# TC37XPD register map
Vendor: Infineon; Series: ATVMC; File version: 100
CPU: other r0p0, little endian, MPU, FPU, vendor SysTick, 4 interrupt priority bits
Registers are 32-bit, read-write, reset 0x0 unless marked. A register's access mark holds for its fields unless they carry their own. Offsets are from the block's base; [hi:lo] are bit positions; lines under a group give offsets from that group; {n}, {i} and the like mark numbered series.

## ASCLIN0
Base 0xF0000600
Same registers: ASCLIN{n} {0xF0000600+0x100*n} (n=1..9), ASCLIN10 0xF02C0A00, ASCLIN11 0xF02C0B00
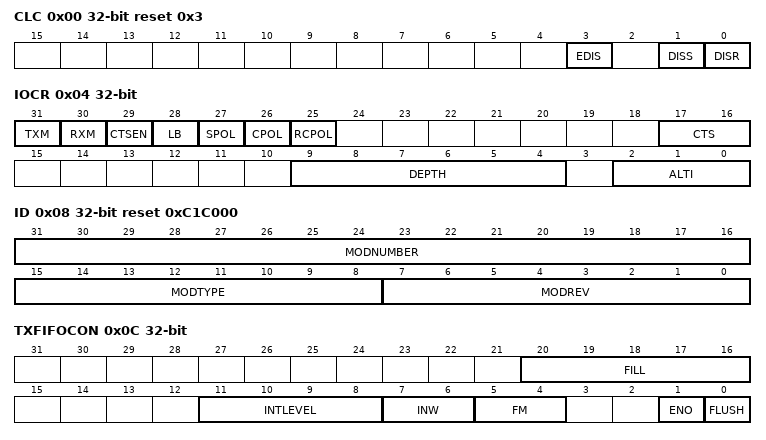
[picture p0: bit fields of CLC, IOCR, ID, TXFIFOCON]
0x00 CLC access per field reset 0x3 — Clock Control Register resetvalue={Application Reset:0x3}
  [3] EDIS rw — Sleep Mode Enable Control EDIS. Used to control module s sleep mode that is if the sensitivity of the module to the sleep signal is enabled to react to it or disabled to ignore it.
  [1] DISS ro — Module Disable Status Bit DISS. Bit indicates the current status of the module.
  [0] DISR rw — Module Disable Request Bit DISR. Used for enable disable control of the module.
0x04 IOCR access per field (reset mask 0xFFFFFFF) — Input and Output Control Register resetvalue={Application Reset:0x0}
  [31] TXM ro — Transmit Monitor TXM. Shows the status of the transmit signal.
  [30] RXM ro — Receive Monitor RXM. Shows the status of the receive signal.
  [29] CTSEN rw — Input Signal CTS Enable CTSEN. Enables the sensitivity of the module to the external CTS signal. If disabled the CTS signal is considered being permanently active.
  [28] LB rw — Loop Back Mode LB. Enables the in module connection of the transmit signal to receive signal. If Loop back is enabled the module can be run and tested without an external connection in ASC and SPI modes. In LIN mode loopback should not be used because the module can be either master or slave.
  [27] SPOL rw — Slave Polarity in Synchronous Mode SPOL. Defines the idle level of the SLSO signal which is the level outside the data transmission leading and trailing time intervals.
  [26] CPOL rw — Clock Polarity in Synchronous Mode CPOL. CPOL defines the idle level of the clock signal if the module is set in the SPI mode. The idle level is the level outside the data transmission time intervals. Default is low level.
  [25] RCPOL rw — RTS CTS Polarity RCPOL. RCPOL defines the active level or the RTS and CTS signals. Active means ready clear to send.
  [17:16] CTS rw — CTS Select CTS. Selects the CTS input pin out of maximum four possible.
  [9:4] DEPTH rw — Digital Glitch Filter Depth DEPTH. DEPTH determines the number of port input samples clocked with microticks that are taken into account for the calculation of the floating average. The higher the DEPTH is chosen to be the longer the glitches that are suppressed and the longer the delay of the input signal introduced by this filter.
  [2:0] ALTI rw — Alternate Input Select ALTI. Selects the alternate input for the RX signal
0x08 ID ro reset 0xC1C000 (reset mask 0xFFFFFF00) — Module Identification Register resetvalue={Application Reset:0x0C1C000}
  [31:16] MODNUMBER — Module Number Value MODNUMBER. This bit field together with MODTYPE uniquely identifies a module.
  [15:8] MODTYPE — Module Type MODTYPE. This bit field is C0 H . It defines a 32 bit module.
  [7:0] MODREV — Module Revision Number MODREV. MODREV defines the module revision number. The value of a module revision starts with 01 H first revision .
0x0C TXFIFOCON access per field — TX FIFO Configuration Register resetvalue={Application Reset:0x0}
  [20:16] FILL ro — FIFO Filling Level FILL. Read only bit field containing the current filling level of the FIFO.
  [11:8] INTLEVEL rw — FIFO Interrupt Level INTLEVEL. Defines the filling level that triggers a re fill interrupt or DMA access. An interrupt is generated when the filling level falls to INTLEVEL or below each time when a data byte is taken out of the FIFO. This behavior corresponds to the Combined Compatibility Mode of interrupt generation. See also Single Move Mode and Batch Move Mode for two additional modes.
  [7:6] INW rw — Transmit FIFO Inlet Width INW. Defines the number of bytes written to the Tx FIFO with one FPI bus write.
  [5:4] FM rw — TXFIFO Mode FM. Selects between the TXFIFO Modes.
  [1] ENO rw — Transmit FIFO Outlet Enable ENO. Enables the TxFIFO outlet. In SPI and ASC modes data transmission starts immediately when the data is available whereas in LIN case the transmission start is controlled by the protocol engine.
  [0] FLUSH wo — Flush the transmit FIFO FLUSH. Write of 1 brings the Tx FIFO in empty state. Write of 0 has no effect.
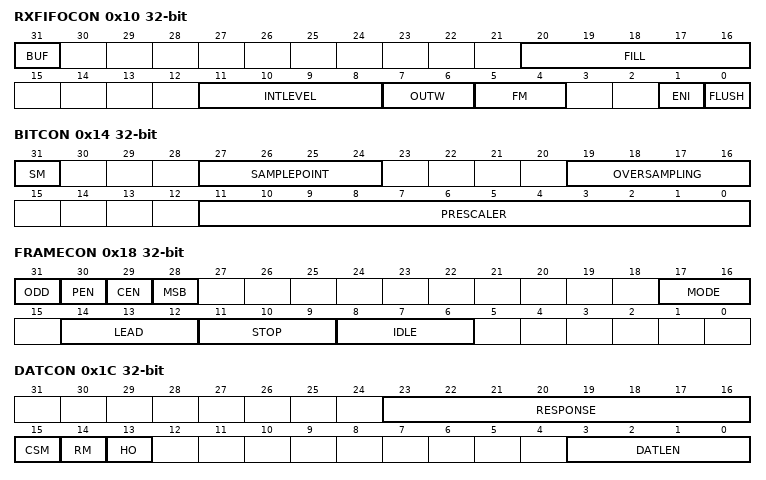
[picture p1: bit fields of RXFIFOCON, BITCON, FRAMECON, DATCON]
0x10 RXFIFOCON access per field — RX FIFO Configuration Register resetvalue={Application Reset:0x0}
  [31] BUF rw — Receive Buffer Mode BUF. If this bit is zero then the RXFIFO behaves normally as described in this document. If this bit is set the RXFIFO behaves as simple 32 bit one stage RX buffer which is overwritten with each new received data. The received bits appear in the RXDATA register on the lowest bit locations. The upper locations are padded with zeros.
  [20:16] FILL ro — FIFO Filling Level FILL. Read only bit field containing the current filling level of the FIFO.
  [11:8] INTLEVEL rw — FIFO Interrupt Level INTLEVEL. Defines the filling level that triggers a drain interrupt or DMA access. An interrupt is generated when the filling level rises to INTLEVEL or beyond each time when a data byte is delivered to the FIFO. This behavior corresponds to the Combined Compatibility Mode of interrupt generation. See also Single Move Mode and Batch Move Mode for two additional modes.
  [7:6] OUTW rw — Receive FIFO Outlet Width OUTW. Defines the number of bytes read to the Rx FIFO with one FPI bus read.
  [5:4] FM rw — RXFIFO Mode FM. Selects between the RXFIFO Modes.
  [1] ENI rw — Receive FIFO Inlet Enable ENI. Enables the receiver and the filling of the Rx FIFO through the shift register. In LIN slave mode this bit is set by hardware after the correct reception of the sync byte. The software can clear this bit after reception of an foreign ID in order to suppress the reception of the following response.
  [0] FLUSH wo — Flush the receive FIFO FLUSH. Write of 1 brings the Rx FIFO in empty state. Write of 0 has no effect.
0x14 BITCON — Bit Configuration Register resetvalue={Application Reset:0x0}
  [31] SM — Sample Mode SM. Number of samples per bit.
  [27:24] SAMPLEPOINT — Sample Point Position SAMPLEPOINT. Programmable in the range of 0 to 15 according to the CROSSREFERENCE . For example if three sample points at position 7 8 9 are required this bit field would contain 9. In SPI mode this bit field 1 defines the length of the first SCLK half period in ticks. Values equal or higher then the OVERSAMPLING value are forbidden.
  [19:16] OVERSAMPLING — Oversampling Factor OVERSAMPLING. Defines the bit length in ticks in the range of 1 to 16. The lengths of 1 to 3 are not allowed. The position of the sampling points is shown in CROSSREFERENCE .
  [11:0] PRESCALER — Prescaling of the Fractional Divider PRESCALER. Prescaler bit field with values in the range of 0 to 4095 defining division ratios from 1 to 4096. Used also as a microtick generator for the input digital filter.
0x18 FRAMECON — Frame Control Register resetvalue={Application Reset:0x0}
  [31] ODD — Parity Type ODD. Defines the type of parity bit attached to the data bits. This setting is valid for all modes of operation ASC LIN SPI .
  [30] PEN — Parity Enable PEN. Enables the parity bit attached to the data bits. Parity bit can be used for ASC and SPI protocols. The standard LIN bytes do not use this parity bit.
  [29] CEN — Collision Detection Enable CEN. Enables the collision detection mechanism.
  [28] MSB — Shift Direction MSB. Defines the shift direction of the shift register. Relevant for the SPI mode. In ASC and LIN modes should be set to zero. Parity bit is shifted out last independently of the shift direction.
  [17:16] MODE — Mode Selection MODE. This bit field defines the basic operating mode of the module. In INIT mode all outputs are at inactive level and the module does not respond to the input signals. Changing the mode of the module must be done by switching first to INIT mode and then to the other mode. The SCLK signal generated by the module is active only in the SPI mode. The CTS output generated by the module is active only in the ASC mode.
  [14:12] LEAD — Duration of the Leading Delay LEAD. Defines the leading delay in bit times in SPI mode. Has no meaning in the ASC mode. In LIN mode this is a delay inserted between the end of the break and the start of the sync character.
  [11:9] STOP — Number of Stop Bits STOP. Defines the number of stop bits in ASC and LIN mode or the trailing delay in SPI mode. In ASC mode standard values are 1 and 2. In LIN mode standard value is 1. In SPI mode there is no standard value. Nevertheless all settings are possible in all modes.
  [8:6] IDLE — Duration of the IDLE delay IDLE. Defines the duration of the IDLE delay in bit times. If more characters are available in the TXFIFO this is the pause inserted between the characters. In the SPI mode this is the idle time between the frames. In the ASC and LIN mode this is the pause inserted between transmission of bytes. Idle also applies to the pause between the header and the response response space . The collision detection runs in parallel to the idle delay and in LIN master mode it may extend the time between two bytes for one bit length. This effect may occur if the round trip delay including the digital filter delay is longer than the idle delay. For LIN slave mode use IDLE 0.
0x1C DATCON — Data Configuration Register resetvalue={Application Reset:0x0}
  [23:16] RESPONSE — Response Timeout Threshold Value RESPONSE. Defines the timer limit in the range of 1 to 256 bit times.
  [15] CSM — Checksum Mode CSM. Defines if the classic or the enhanced checksum will be calculated by the checksum block.
  [14] RM — Response Mode RM. Defines if the RESPONSE bit field defines a LIN Response or LIN Frame timeout threshold. See CROSSREFERENCE .
  [13] HO — Header Only HO. Defines if the LIN frame shall consist of a header and response or of a header only.
  [3:0] DATLEN — Data Length DATLEN. Defines the number of bits in a character. In the ASC mode standard length is 7 8 or 9 bits. In the SPI mode there is no standard length. In ASC and SPI modes any length from 2 to 16 bits is possible although not standard for some protocols. In LIN mode standard length is 8 bits per character. Therefore this field defines the number of data bytes of the response.
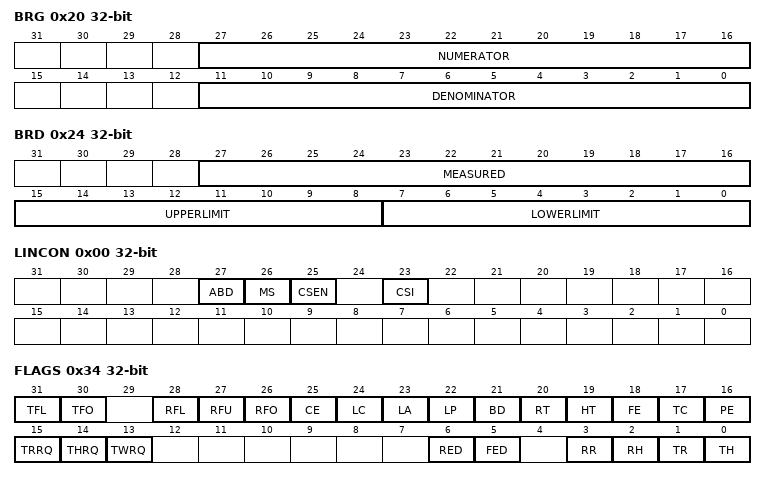
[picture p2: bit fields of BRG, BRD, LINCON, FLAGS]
0x20 BRG — Baud Rate Generation Register resetvalue={Application Reset:0x0}
  [27:16] NUMERATOR — Numerator NUMERATOR. Defines the numerator of the fractional divider in a range of 0 to 4095. Programmed by software. The setting of 0 is not allowed.
  [11:0] DENOMINATOR — Denominator DENOMINATOR. Programmed by software in a range of 0 to 4095. The setting of 0 is not allowed If the module is used as ASC SPI LIN master and LIN slave without autobaud detection this value determines the baud rate. In slave mode with autobaud detection it contains the nominal value. For the value measured by the autobaud detection hardware see the BRD register.
0x24 BRD access per field — Baud Rate Detection Register resetvalue={Application Reset:0x0}
  [27:16] MEASURED ro — Measured Value of 8 bits from Sync Field MEASURED. This bit field contains the measured value of the duration of 8 bits form the sync field of the LIN header in microticks. It is automatically loaded in the denominator of the fractional divider in case of LIN slave operation with autobaud detection.
  [15:8] UPPERLIMIT rw — Upper Limit UPPERLIMIT. This field defines the 8 most significant bits of the 12 bit compare value. The lower four bits are 1000 . See CROSSREFERENCE .
  [7:0] LOWERLIMIT rw — Lower Limit LOWERLIMIT. This field defines the 8 most significant bits of the 12 bit compare value. The lower four bits are 1000 . See CROSSREFERENCE .
0x28 LIN group
  0x00 LINCON — LIN Control Register resetvalue={Application Reset:0x0}
    [27] ABD — Autobaud Detection ABD. Enables the autobaud detection feature in LIN slave mode. In all other operating modes of the module LIN master ASC SPI not effective. If the autobaud detection is disabled the oscillator precision of the slave is sufficient the sync field byte field and stop bit is checked if correct. If not correct a framing error is triggered.
    [26] MS — Master Slave Mode MS. Configures if the module in LIN mode operates as master or as slave.
    [25] CSEN — Hardware Checksum Enable CSEN. Enables the hardware checksum generation and checking.
    [23] CSI — Checksum Injection CSI. Defines if the received checksum byte is written into the RXFIFO or not. See CROSSREFERENCE .
  0x04 LINBTIMER — LIN Break Timer Register resetvalue={Application Reset:0x0}
    [5:0] BREAK — Break Pulse Generation and Detection BREAK. In LIN slave mode this bit field defines the duration of the detection threshold for the break pulse. In LIN master mode this bit field defines the duration of the transmitted break pulse. The time unit is bit time.
  0x08 LINHTIMER — LIN Header Timer Register resetvalue={Application Reset:0x0}
    [7:0] HEADER — Header Timeout Threshold Value HEADER. Defines the timer limit in the range of 0 to 255 bit times.
0x34 FLAGS ro — Flags Register resetvalue={Application Reset:0x0}
  [31] TFL — Transmit FIFO Level Flag TFL. This flag signals whenever a TXFIFO refill interrupt if enabled is generated based on TXFIFOCON.FM mode.
  [30] TFO — Transmit FIFO Overflow Flag TFO. Signals an overflow error. If enabled an error interrupt is triggered.
  [28] RFL — Receive FIFO Level Flag RFL. This flag signals whenever a RXFIFO fill interrupt is generated based on RXFIFOCON.FM mode.
  [27] RFU — Receive FIFO Underflow Flag RFU. Signals an underflow error. If enabled an error interrupt is triggered. See also CROSSREFERENCE .
  [26] RFO — Receive FIFO Overflow Flag RFO. Signals an overflow error. If enabled an error interrupt is triggered.
  [25] CE — Collision Detection Error Flag CE. When transmitting signals if the transmitted data differs from the received data. If enabled an error interrupt is triggered in case of a mismatch. Collision detection is mandatory only when supporting LIN version 2.1.
  [24] LC — LIN Checksum Error Flag LC. Signals checksum error when receiving response if the internally calculated checksum is different than the received checksum. If enabled an error interrupt is triggered.
  [23] LA — LIN Autobaud Detection Error Flag LA. Signals baudrate outside the range defined by BRD .LOWERLIMIT and BRD .UPPERLIMIT.
  [22] LP — LIN Parity Error Flag LP. Signals parity error in the LIN identifier. If enabled an error interrupt is triggered. Applies to LIN mode only. LIN parity error occurs if the internally calculated parity bits are not equal to the received parity bits.
  [21] BD — Break Detected Flag BD. Signals a detection of a break pulse. If enabled an error interrupt is triggered. Slave mode only.
  [20] RT — Response Timeout Flag RT. Signals violation of the response or frame duration limit as defined in DATCON .RM bit. If enabled an error interrupt is triggered.
  [19] HT — Header Timeout Flag HT. Signals violation of the header duration limit. If enabled an error interrupt is triggered.
  [18] FE — Framing Error Flag FE. Signals framing error. If enabled an error interrupt is triggered. Framing error occurs if 0 is received at a stop bit position. If autobaud detection is deactivated then the sync field is checked for framing error.
  [17] TC — Transmission Completed Flag TC. Signals an end of an ASC or SPI frame. This bit is set after the last stop bit transmission in ASC mode or after the trailing delay in case of SPI mode. In LIN mode if the node is transmitting a header this flag is set after each transmission break incl lead field Sync field or PID field. If the node is transmitting a response this flag is set after each byte is transmitted. If enabled an EX interrupt is triggered. Should be cleared by software.
  [16] PE — Parity Error Flag PE. Signals parity error. If enabled an error interrupt is triggered. Parity error occurs if the internally calculated parity bit is not equal to the received parity bit.
  [15] TRRQ — Transmit Response Request Flag TRRQ. Signals that transmission of response has been requested. No interrupt triggered. As soon as the response transmission starts the bit is cleared by the hardware.
  [14] THRQ — Transmit Header Request Flag THRQ. Signals that transmission of header has been requested. No interrupt triggered. As soon as the header transmission starts the bit is cleared by the hardware.
  [13] TWRQ — Transmit Wake Request Flag TWRQ. Signals that transmission of wake has been requested. No interrupt triggered. As soon as the wake pulse transmission starts the bit is cleared by the hardware.
  [6] RED — Rising Edge from Level 0 to Level 1 Detected RED. This bit is set by hardware when a rising edge is detected on the RX line.
  [5] FED — Falling Edge from Level 1 to Level 0 Detected FED. This bit is set by hardware when a falling edge is detected on the RX line.
  [3] RR — Receive Response End Flag RR. Signals that RESPONSE RX END event. Set by hardware clear by software. If enabled a receive interrupt is triggered.
  [2] RH — Receive Header End Flag RH. Signals that HEADER RX END event. Set by hardware clear by software. If enabled a receive interrupt is triggered.
  [1] TR — Transmit Response End Flag TR. Signals that RESPONSE TX END event. Set by hardware clear by software. If enabled a transmit interrupt is triggered.
  [0] TH — Transmit Header End Flag TH. Signals the HEADER TX END event. Set by hardware clear by software. If enabled a transmit interrupt is triggered.
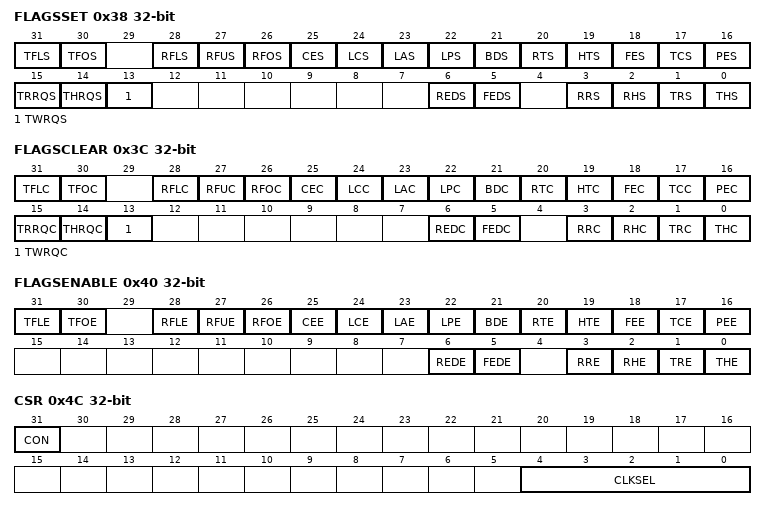
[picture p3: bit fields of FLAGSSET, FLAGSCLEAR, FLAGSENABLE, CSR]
0x38 FLAGSSET wo — Flags Set Register resetvalue={Application Reset:0x0}
  [31] TFLS — Flag Set Bit TFLS. Write of 8220 1 8221 in this bit sets the bit at the corresponding position in the FLAGS register.
  [30] TFOS — Flag Set Bit TFOS. Write of 8220 1 8221 in this bit sets the bit at the corresponding position in the FLAGS register.
  [28] RFLS — Flag Set Bit RFLS. Write of 8220 1 8221 in this bit sets the bit at the corresponding position in the FLAGS register.
  [27] RFUS — Flag Set Bit RFUS. Write of 8220 1 8221 in this bit sets the bit at the corresponding position in the FLAGS register.
  [26] RFOS — Flag Set Bit RFOS. Write of 8220 1 8221 in this bit sets the bit at the corresponding position in the FLAGS register.
  [25] CES — Flag Set Bit CES. Write of 8220 1 8221 in this bit sets the bit at the corresponding position in the FLAGS register.
  [24] LCS — Flag Set Bit LCS. Write of 8220 1 8221 in this bit sets the bit at the corresponding position in the FLAGS register.
  [23] LAS — Flag Set Bit LAS. Write of 8220 1 8221 in this bit sets the bit at the corresponding position in the FLAGS register.
  [22] LPS — Flag Set Bit LPS. Write of 8220 1 8221 in this bit sets the bit at the corresponding position in the FLAGS register.
  [21] BDS — Flag Set Bit BDS. Write of 8220 1 8221 in this bit sets the bit at the corresponding position in the FLAGS register.
  [20] RTS — Flag Set Bit RTS. Write of 8220 1 8221 in this bit sets the bit at the corresponding position in the FLAGS register.
  [19] HTS — Flag Set Bit HTS. Write of 8220 1 8221 in this bit sets the bit at the corresponding position in the FLAGS register.
  [18] FES — Flag Set Bit FES. Write of 8220 1 8221 in this bit sets the bit at the corresponding position in the FLAGS register.
  [17] TCS — Flag Set Bit TCS. Write of 8220 1 8221 in this bit sets the bit at the corresponding position in the FLAGS register.
  [16] PES — Flag Set Bit PES. Write of 8220 1 8221 in this bit sets the bit at the corresponding position in the FLAGS register.
  [15] TRRQS — Flag Set Bit TRRQS. Write of 8220 1 8221 in this bit sets the bit at the corresponding position in the FLAGS register.
  [14] THRQS — Flag Set Bit THRQS. Write of 8220 1 8221 in this bit sets the bit at the corresponding position in the FLAGS register.
  [13] TWRQS — Flag Set Bit TWRQS. Write of 8220 1 8221 in this bit sets the bit at the corresponding position in the FLAGS register.
  [6] REDS — Flag Set Bit REDS. Write of 8220 1 8221 in this bit sets the bit at the corresponding position in the FLAGS register.
  [5] FEDS — Flag Set Bit FEDS. Write of 8220 1 8221 in this bit sets the bit at the corresponding position in the FLAGS register.
  [3] RRS — Flag Set Bit RRS. Write of 8220 1 8221 in this bit sets the bit at the corresponding position in the FLAGS register.
  [2] RHS — Flag Set Bit RHS. Write of 8220 1 8221 in this bit sets the bit at the corresponding position in the FLAGS register.
  [1] TRS — Flag Set Bit TRS. Write of 8220 1 8221 in this bit sets the bit at the corresponding position in the FLAGS register.
  [0] THS — Flag Set Bit THS. Write of 8220 1 8221 in this bit sets the bit at the corresponding position in the FLAGS register.
0x3C FLAGSCLEAR wo — Flags Clear Register resetvalue={Application Reset:0x0}
  [31] TFLC — Flag Clear Bit TFLC. Write of 8220 1 8221 in this bit clears the bit at the corresponding position in the FLAGS register.
  [30] TFOC — Flag Clear Bit TFOC. Write of 8220 1 8221 in this bit clears the bit at the corresponding position in the FLAGS register.
  [28] RFLC — Flag Clear Bit RFLC. Write of 8220 1 8221 in this bit clears the bit at the corresponding position in the FLAGS register.
  [27] RFUC — Flag Clear Bit RFUC. Write of 8220 1 8221 in this bit clears the bit at the corresponding position in the FLAGS register.
  [26] RFOC — Flag Clear Bit RFOC. Write of 8220 1 8221 in this bit clears the bit at the corresponding position in the FLAGS register.
  [25] CEC — Flag Clear Bit CEC. Write of 8220 1 8221 in this bit clears the bit at the corresponding position in the FLAGS register.
  [24] LCC — Flag Clear Bit LCC. Write of 8220 1 8221 in this bit clears the bit at the corresponding position in the FLAGS register.
  [23] LAC — Flag Clear Bit LAC. Write of 8220 1 8221 in this bit clears the bit at the corresponding position in the FLAGS register.
  [22] LPC — Flag Clear Bit LPC. Write of 8220 1 8221 in this bit clears the bit at the corresponding position in the FLAGS register.
  [21] BDC — Flag Clear Bit BDC. Write of 8220 1 8221 in this bit clears the bit at the corresponding position in the FLAGS register.
  [20] RTC — Flag Clear Bit RTC. Write of 8220 1 8221 in this bit clears the bit at the corresponding position in the FLAGS register.
  [19] HTC — Flag Clear Bit HTC. Write of 8220 1 8221 in this bit clears the bit at the corresponding position in the FLAGS register.
  [18] FEC — Flag Clear Bit FEC. Write of 8220 1 8221 in this bit clears the bit at the corresponding position in the FLAGS register.
  [17] TCC — Flag Clear Bit TCC. Write of 8220 1 8221 in this bit clears the bit at the corresponding position in the FLAGS register.
  [16] PEC — Flag Clear Bit PEC. Write of 8220 1 8221 in this bit clears the bit at the corresponding position in the FLAGS register.
  [15] TRRQC — Flag Clear Bit TRRQC. Write of 8220 1 8221 in this bit clears the bit at the corresponding position in the FLAGS register.
  [14] THRQC — Flag Clear Bit THRQC. Write of 8220 1 8221 in this bit clears the bit at the corresponding position in the FLAGS register.
  [13] TWRQC — Flag Clear Bit TWRQC. Write of 8220 1 8221 in this bit clears the bit at the corresponding position in the FLAGS register.
  [6] REDC — Flag Clear Bit REDC. Write of 8220 1 8221 in this bit clears the bit at the corresponding position in the FLAGS register.
  [5] FEDC — Flag Clear Bit FEDC. Write of 8220 1 8221 in this bit clears the bit at the corresponding position in the FLAGS register.
  [3] RRC — Flag Clear Bit RRC. Write of 8220 1 8221 in this bit clears the bit at the corresponding position in the FLAGS register.
  [2] RHC — Flag Clear Bit RHC. Write of 8220 1 8221 in this bit clears the bit at the corresponding position in the FLAGS register.
  [1] TRC — Flag Clear Bit TRC. Write of 8220 1 8221 in this bit clears the bit at the corresponding position in the FLAGS register.
  [0] THC — Flag Clear Bit THC. Write of 8220 1 8221 in this bit clears the bit at the corresponding position in the FLAGS register.
0x40 FLAGSENABLE — Flags Enable Register resetvalue={Application Reset:0x0}
  [31] TFLE — Flag Enable Bit TFLE. This bit enables the interrupt for the flag at the corresponding position in the FLAGS register.
  [30] TFOE — Flag Enable Bit TFOE. This bit enables the interrupt for the flag at the corresponding position in the FLAGS register.
  [28] RFLE — Flag Enable Bit RFLE. This bit enables the interrupt for the flag at the corresponding position in the FLAGS register.
  [27] RFUE — Flag Enable Bit RFUE. This bit enables the interrupt for the flag at the corresponding position in the FLAGS register.
  [26] RFOE — Flag Enable Bit RFOE. This bit enables the interrupt for the flag at the corresponding position in the FLAGS register.
  [25] CEE — Flag Enable Bit CEE. This bit enables the interrupt for the flag at the corresponding position in the FLAGS register.
  [24] LCE — Flag Enable Bit LCE. This bit enables the interrupt for the flag at the corresponding position in the FLAGS register.
  [23] LAE — Flag Enable Bit LAE. This bit enables the interrupt for the flag at the corresponding position in the FLAGS register.
  [22] LPE — Flag Enable Bit LPE. This bit enables the interrupt for the flag at the corresponding position in the FLAGS register.
  [21] BDE — Flag Enable Bit BDE. This bit enables the interrupt for the flag at the corresponding position in the FLAGS register.
  [20] RTE — Flag Enable Bit RTE. This bit enables the interrupt for the flag at the corresponding position in the FLAGS register.
  [19] HTE — Flag Enable Bit HTE. This bit enables the interrupt for the flag at the corresponding position in the FLAGS register.
  [18] FEE — Flag Enable Bit FEE. This bit enables the interrupt for the flag at the corresponding position in the FLAGS register.
  [17] TCE — Flag Enable Bit TCE. This bit enables the interrupt for the flag at the corresponding position in the FLAGS register.
  [16] PEE — Flag Enable Bit PEE. This bit enables the interrupt for the flag at the corresponding position in the FLAGS register.
  [6] REDE — Flag Enable Bit REDE. This bit enables the interrupt for the flag at the corresponding position in the FLAGS register.
  [5] FEDE — Flag Enable Bit FEDE. This bit enables the interrupt for the flag at the corresponding position in the FLAGS register.
  [3] RRE — Flag Enable Bit RRE. This bit enables the interrupt for the flag at the corresponding position in the FLAGS register.
  [2] RHE — Flag Enable Bit RHE. This bit enables the interrupt for the flag at the corresponding position in the FLAGS register.
  [1] TRE — Flag Enable Bit TRE. This bit enables the interrupt for the flag at the corresponding position in the FLAGS register.
  [0] THE — Flag Enable Bit THE. This bit enables the interrupt for the flag at the corresponding position in the FLAGS register.
0x44 TXDATA wo — Transmit Data Register resetvalue={Application Reset:0x0}
  [31:0] DATA — Data DATA. Writing to this bit field writes the content to the TXFIFO depending on the write width 8 16 or 32 bit configured in TXFIFOCON.INW . A read access to this register returns 0x0.
0x48 RXDATA ro — Receive Data Register resetvalue={Application Reset:0x0}
  [31:0] DATA — Data DATA. Reading from this bit field takes content from the RXFIFO depending on the read width 8 16 or 32 bit configured in RXFIFOCON.OUTW . A write access to this register has no effect.
0x4C CSR access per field — Clock Selection Register resetvalue={Application Reset:0x0}
  [31] CON ro — Clock On Flag CON. Shows if the clock in the bit time domain is switched on or off. Many configuration registers can be written only if this bit shows 0 see header of registers IOCR BITCON FRAMECON BRG BRD LINCON LINBTIMER LINHTIMER .
  [4:0] CLKSEL rw — Baud Rate Logic Clock Select CLKSEL
0x50 RXDATAD ro — Receive Data Debug Register resetvalue={Application Reset:0x0}
  [31:0] DATA — Data DATA. Reading from this bit field takes content from the RXFIFO depending on the read width 8 16 or 32 bit see RXFIFOCON.OUTW but does not influence the read pointer of the RXFIFO. A write access to this register has no effect.
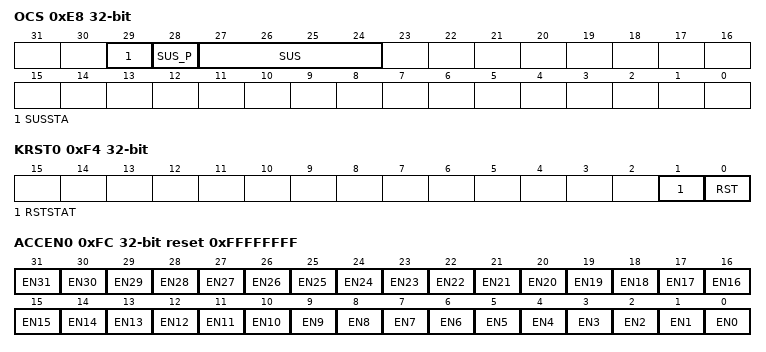
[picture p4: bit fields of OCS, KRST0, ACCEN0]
0xE8 OCS access per field — OCDS Control and Status resetvalue={Debug Reset:0x0,PowerOn Reset:0x0}
  [29] SUSSTA ro — Suspend State SUSSTA
  [28] SUS_P wo — SUS Write Protection SUS P. SUS is only written when SUS P is 1 otherwise unchanged. Read as 0.
  [27:24] SUS rw — OCDS Suspend Control SUS. Controls the sensitivity to the suspend signal coming from the OCDS Trigger Switch OTGS
0xEC KRSTCLR wo — Kernel Reset Status Clear Register resetvalue={Application Reset:0x0}
  [0] CLR — Kernel Reset Status Clear CLR. Read always as 0.
0xF0 KRST1 — Kernel Reset Register 1 resetvalue={Application Reset:0x0}
  [0] RST — Kernel Reset RST. This reset bit can be used to request for a kernel reset. The kernel reset will be executed if the reset bits of both kernel reset registers is set. The RST bit will be cleared re set to 180 0 180 by the BPI FPI after the kernel reset was executed.
0xF4 KRST0 access per field — Kernel Reset Register 0 resetvalue={Application Reset:0x0}
  [1] RSTSTAT ro — Kernel Reset Status RSTSTAT. This bit indicates wether a kernel reset was executed or not. This bit is set by the BPI FPI after the execution of a kernel reset in the same clock cycle both reset bits. This bit can be cleared by writing with 1 to the CLR bit in the related KRSTCLR register.
  [0] RST rw — Kernel Reset RST. This reset bit can be used to request for a kernel reset. The kernel reset will be executed if the reset bits of both kernel registers are set. The RST bit will be cleared re set to 0 by the BPI FPI after the kernel reset was executed.
0xFC ACCEN0 reset 0xFFFFFFFF — Access Enable Register 0 resetvalue={Application Reset:0x0FFFFFFFF}
  [n] EN{n} (n=0..31) — Access Enable for Master TAG ID 31 EN31. This bit enables write access to the module kernel addresses for transactions with the Master TAG ID n
